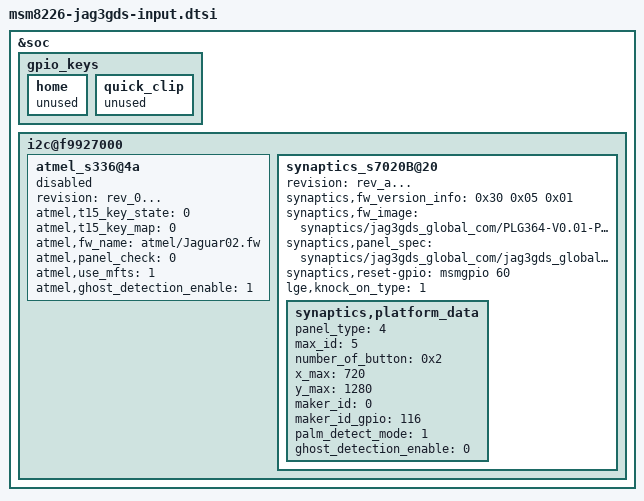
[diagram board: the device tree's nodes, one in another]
/* Copyright (c) 2013, LGE Electronics. All rights reserved.
 *
 * This program is free software; you can redistribute it and/or modify
 * it under the terms of the GNU General Public License version 2 and
 * only version 2 as published by the Free Software Foundation.
 *
 * This program is distributed in the hope that it will be useful,
 * but WITHOUT ANY WARRANTY; without even the implied warranty of
 * MERCHANTABILITY or FITNESS FOR A PARTICULAR PURPOSE.  See the
 * GNU General Public License for more details.
 */

&soc {
	gpio_keys {
		home {
			unused;
		};

		quick_clip {
			unused;
		};
	};

	i2c@f9927000 { /* BLSP1 QUP5 */
		atmel_s336@4a {
			revision = "rev_0...";
			status = "disable";
			atmel,t15_key_state = <0>;
			atmel,t15_key_map = <0>;
			atmel,fw_name = "atmel/Jaguar02.fw";
			atmel,panel_check = <0>;
			atmel,use_mfts = <1>;
			atmel,ghost_detection_enable = <1>;
		};
		synaptics_s7020B@20 {
			revision = "rev_a...";
			status = "ok";
			synaptics,fw_version_info = <0x30 0x05 0x01>;
			synaptics,fw_image = "synaptics/jag3gds_global_com/PLG364-V0.01-PR1606308-DS4.3.5.1.16_30050101.img";
			synaptics,panel_spec = "synaptics/jag3gds_global_com/jag3gds_global_com_limit.txt";
			synaptics,reset-gpio = <&msmgpio 60 0x00>;
			lge,knock_on_type = <1>;
			synaptics,platform_data	{
				/* firmware image depends on this value, temporarily used */
				/* 0: No image(default), 1: W3DS(TIM BR)(PLG312_T001), 2: W3S(VDF)(PLG311_T001), 3:X3, 4:W5DS, 5:W5S ... */
				panel_type = <4>;
				max_id = <5>;
				number_of_button = <0x2>;
				x_max = <720>;
				y_max = <1280>;
				/*maker_id  disable(0), enable(1)*/
				maker_id = <0>;
				maker_id_gpio = <116>;
				palm_detect_mode = <1>;
				ghost_detection_enable = <0>;
			};
		};

	};
};
